# NANO103AE_v1 register map
File version: 1.0
Registers are 32-bit, read-write, reset 0x0 unless marked. A register's access mark holds for its fields unless they carry their own. Offsets are from the block's base; [hi:lo] are bit positions; 'fields as' and 'values as' point back to an identical list.

## I2C0 — I2C Register Map
Base 0x40020000
Same registers: I2C1 0x40120000
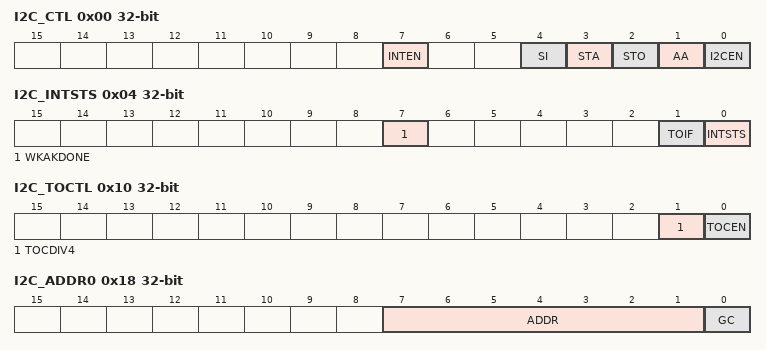
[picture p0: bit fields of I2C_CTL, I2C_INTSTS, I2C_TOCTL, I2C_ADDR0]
0x00 I2C_CTL — I2C Control Register
  [7] INTEN — Interrupt EnableBit
    0=I2C interrupt Disabled; 1=I2C interrupt Enabled
  [4] SI — I2C Status. When a new state is present in the I2C_STATUS register, if the INTEN bit is set, the I2C interrupt is requested. It must write one by software to this bit after the INTSTS (I2C_INTSTS[0]) is set to 1 and the I2C protocol function will go ahead until the STOP is active or the I2CEN is disabled. Note:If software wants to skip clearing INTSTS (I2C_INTSTS[0]), it also can write 1 to SI bit and must set INTEN bit. That INTSTS (I2C_INTSTS[0]) wll be cleared when SI is cleared.
    0=I2C's Status disabled and the I2C protocol function will go ahead; 1=I2C's Status active
  [3] STA — I2C START Command. Setting STA to logic 1 to enter Master mode, the I2C hardware sends a START or repeat START condition to bus when the bus is free.
  [2] STO — I2C STOP Control Bit. In Master mode, setting STO to transmit a STOP condition to bus then I2C controller will check the bus condition if a STOP condition is detected. This bit will be cleared by hardware automatically.
  [1] AA — Assert Acknowledge Control Bit
  [0] I2CEN — I2C Function EnableBit
    0=I2C function Disabled; 1=I2C function Enabled
0x04 I2C_INTSTS — I2C Interrupt Status Register
  [7] WKAKDONE — Wake-up Address Frame Acknowledge Bit Done. Note:This bit can be cleared by writing'1' toit.
    0=The ACK bit cycle of address match frame is not done; 1=The ACK bit cycle of address match frame is done in power-down
  [1] TOIF — Time-out Status. Note:This bit can be cleared by writing '1' to it.
    0=No Time-out flag; 1=Time-out flag active and it is set by hardware. It can interrupt CPU when INTEN bit is set
  [0] INTSTS — I2C STATUS's Interrupt Status. When a new I2C state is present in the I2C_STATUS register, the INTSTS flag is set by hardware. If bit INTEN (I2C_CTL [7]) is set, the I2C interrupt is requested.This bit must be cleared by software writing '1' . Note:If software wants to skip clearing INTSTS, it can also write 1 to SI (I2C_CTL [4]) bit and must set INTEN (I2C_CTL [7]) bit. INISTS wll be cleared when SI is cleared.
0x08 I2C_STATUS ro reset 0xF8
  [7:0] STATUS — I2C Status Bits (Read Only)
0x0C I2C_CLKDIV — I2C Clock Divided Register
  [7:0] DIVIDER — I2C Clock DividedBits. Note:The minimum value of I2C_CLKDIV is 4.
0x10 I2C_TOCTL — I2C Time-out Control Register
  [1] TOCDIV4 — Time-out Counter Input Clock Divider by 4. When enabled, the time-out period is extended 4 times.
    0=Time-out counter input clock divider by 4Disabled; 1=Time-out counter input clock divider by 4 Enabled
  [0] TOCEN — Time-out Counter Enable Bit. When this bit is set to enabled and clcok be stretched, the 14 bits time-out counter will start counting.
    0=Time-out counter Disabled; 1=Time-out counter Enabled
0x14 I2C_DAT — I2C Data Register
  [7:0] DAT — I2C Data. Bit [7:0] is located with the 8-bit transferred/received data of I2C serial port.
0x18 I2C_ADDR0 — I2C Slave Address Register0
  [7:1] ADDR — I2C Salve Address Bits. The content of this register is irrelevant when the device is in Master mode. In the Slave mode, the seven most significant bits must be loaded with the device's own address. The device will react if either of the address is matched.
  [0] GC — General Call FunctionControl. Note: Refer to Address Register section for more detailed information..
    0=General Call Function Disabled; 1=General Call Function Enabled
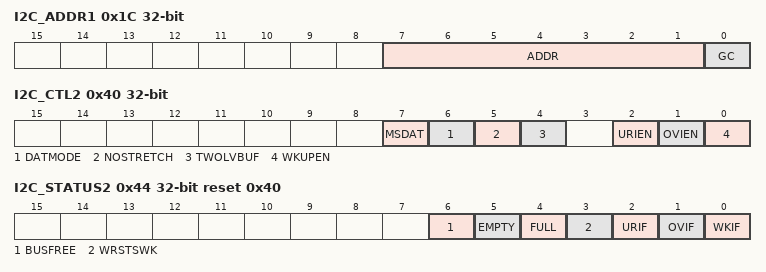
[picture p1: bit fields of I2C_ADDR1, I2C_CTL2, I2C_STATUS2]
0x1C I2C_ADDR1 — I2C Slave Address Register1
  fields as I2C_ADDR0
0x28 I2C_ADDRMSK0 — I2C Slave Address Mask Register0
  [7:1] ADDRMSK — I2C Slave Address Mask Bits. I2C bus controllers support multiple address recognition with two address mask register. When the bit in the address mask register is set to one, it means the received corresponding address bit is don't-care. If the bit is set to zero, that means the received corresponding register bit should be exact the same as address register.
    0=Mask disable (the received corresponding register bit should be exact the same as address register); 1=Mask enable (the received corresponding address bit is don't care)
0x2C I2C_ADDRMSK1 — I2C Slave Address Mask Register1
  fields as I2C_ADDRMSK0
0x40 I2C_CTL2 — I2C Control Register 2
  [7] MSDAT — Master or Slave in Data Mode Enable Control
    0=Master writes data to device; 1=Slave reads data from device
  [6] DATMODE — Data Mode Enable Bit
    0=Data mode Disabled; 1=Data mode Enabled
  [5] NOSTRETCH — I2C BuS Stretch
    0=The I2C SCL bus is stretched by hardware if the SI (I2C_CTL[4]) is not cleared; 1=The I2C SCL bus is not stretched by hardware if the SI is not cleared
  [4] TWOLVBUF — Two Level Buffer Enable Bit
    0=Two level bufferDisabled; 1=Two level bufferEnabled
  [2] URIEN — I2C Underrun Interrupt Control Bit
    0=Underrun event interrupt Disabled; 1=Send a interrupt to system when theTWOLVBUF bit is enabled and there is underrun event happened in transmitted buffer
  [1] OVIEN — I2C Overrun Interrupt Control Bit
    0=Overrun event interrupt Disabled; 1=Send a interrupt to system when the TWOLVBUF bit is enabled and there is overrun event in received buffer
  [0] WKUPEN — I2C Wake-up Function EnableBit
    0=I2C wake-up function Disabled; 1=I2C wake-up function Enabled
0x44 I2C_STATUS2 reset 0x40 — I2C Status Register 2
  [6] BUSFREE — Bus Free Status. The bus status in the controller.
    0=I2C's "Start" condition is detected on the bus; 1=Bus is free and released by "STOP" condition or the controller is disabled
  [5] EMPTY — I2C Two Level Buffer Empty
    0=RX buffer is not empty when the TWOLVBUF = 1; 1=RX buffer is empty when the TWOLVBUF = 1
  [4] FULL — I2C Two Level Buffer Full
    0=TX buffer no full when the TWOLVBUF = 1; 1=TX buffer full when the TWOLVBUF = 1
  [3] WRSTSWK — I2C Read/Write Status Bit in Address Wake-up Frame
    0=Write command is recorded on the address match wake-up frame; 1=Read command is recorded on the address match wake-up frame
  [2] URIF — I2C Underrun Status Bit. Note:This bit can be cleared by writing '1' toit.
    0=The transmitted buffer is not underrun when the TWOLVBUF = 1; 1=The transmitted buffer is underrun when the TWOLVBUF = 1
  [1] OVIF — I2C Overrun Status Bit. Note:This bit can be cleared by writing '1' toit.
    0=The received buffer is not overrun when the TWOLVBUF = 1; 1=The received buffer is overrun when the TWOLVBUF = 1
  [0] WKIF — Wake-up Interrupt Flag. Note:This bit can be cleared by writing '1' toit.
    0=Wake-up flag is inactive; 1=Wake-up flag is active
